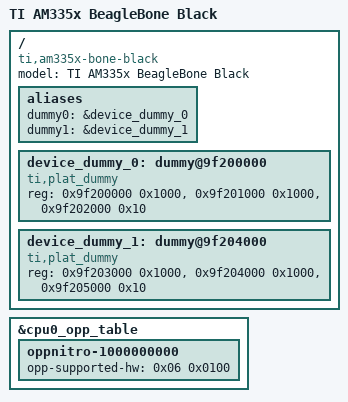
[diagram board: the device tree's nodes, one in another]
/*
 * Copyright (C) 2012 Texas Instruments Incorporated - http://www.ti.com/
 *
 * This program is free software; you can redistribute it and/or modify
 * it under the terms of the GNU General Public License version 2 as
 * published by the Free Software Foundation.
 */
/dts-v1/;

#include "am33xx.dtsi"
#include "am335x-bone-common.dtsi"
#include "am335x-boneblack-common.dtsi"

/ {
	model = "TI AM335x BeagleBone Black";
	compatible = "ti,am335x-bone-black", "ti,am335x-bone", "ti,am33xx";

        aliases {
                dummy0 = &device_dummy_0;
                dummy1 = &device_dummy_1;
        };

	device_dummy_0: dummy@9f200000 {
		compatible = "ti,plat_dummy";
		reg = <0x9f200000 0x1000>,
            <0x9f201000 0x1000>,
			<0x9f202000 0x10>;
    };
	device_dummy_1: dummy@9f204000 {
		compatible = "ti,plat_dummy";
		reg = <0x9f203000 0x1000>,
            <0x9f204000 0x1000>,
			<0x9f205000 0x10>;
    };

};

&cpu0_opp_table {
	/*
	 * All PG 2.0 silicon may not support 1GHz but some of the early
	 * BeagleBone Blacks have PG 2.0 silicon which is guaranteed
	 * to support 1GHz OPP so enable it for PG 2.0 on this board.
	 */
	oppnitro-1000000000 {
		opp-supported-hw = <0x06 0x0100>;
	};
};

